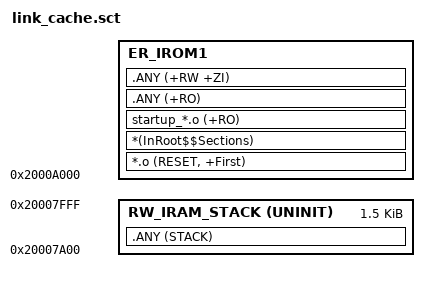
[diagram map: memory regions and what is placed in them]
#! armcc -E --preinclude=..\src\cfg.h

#define SCT_CACHE_BASE     (0x2000A000)
#define SCT_SRAM_LEN       (0x2000B000 - SCT_CACHE_BASE)

LR_IROM1 SCT_CACHE_BASE SCT_SRAM_LEN  
{
    ER_IROM1 +0
    {
        *.o (RESET, +First)
        *(InRoot$$Sections)
        startup_*.o (+RO)
        .ANY (+RO)
        .ANY (+RW +ZI)
    }

    RW_IRAM_STACK 0x20008000-0x600 UNINIT 0x600
    {
        .ANY (STACK)
    }
}
